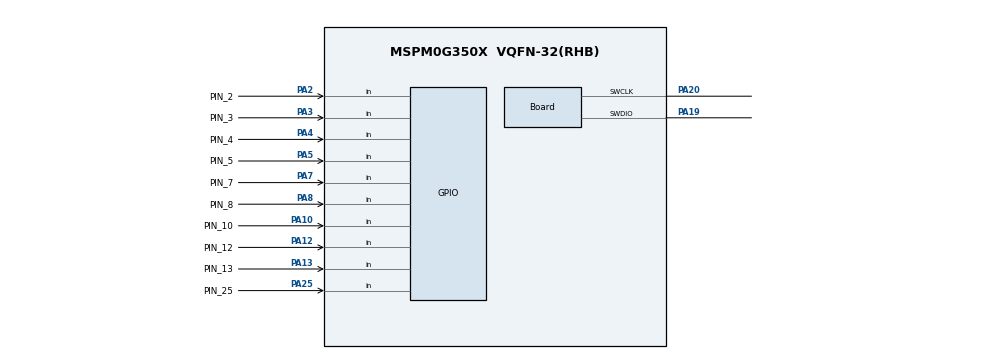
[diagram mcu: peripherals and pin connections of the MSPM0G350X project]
/**
 * @cliArgs --device "MSPM0G350X" --part "Default" --package "VQFN-32(RHB)" --product "mspm0_sdk@2.07.00.06"
 * @versions {"tool":"1.25.0+4268"}
 */

/**
 * Import the modules used in this configuration.
 */
const GPIO          = scripting.addModule("/ti/driverlib/GPIO", {}, false);
const GPIO1         = GPIO.addInstance();
const SYSCTL        = scripting.addModule("/ti/driverlib/SYSCTL");
const SYSTICK       = scripting.addModule("/ti/driverlib/SYSTICK");
const ProjectConfig = scripting.addModule("/ti/project_config/ProjectConfig");

/**
 * Write custom configuration values to the imported modules.
 */
const mux6       = system.clockTree["FCCSELCLKMUX"];
mux6.inputSelect = "FCCSELCLKMUX_SYSOSC";

const mux11       = system.clockTree["SYSCTLMUX"];
mux11.inputSelect = "SYSCTLMUX_LFCLK";

const oscillator2           = system.clockTree["SYSOSC"];
oscillator2.frequencySelect = 4;

GPIO1.$name                               = "GPIO_GRP_0";
GPIO1.port                                = "PORTA";
GPIO1.associatedPins.create(10);
GPIO1.associatedPins[0].assignedPin       = "4";
GPIO1.associatedPins[0].$name             = "PIN_4";
GPIO1.associatedPins[0].direction         = "INPUT";
GPIO1.associatedPins[0].pin.$assign       = "PA4";
GPIO1.associatedPins[1].$name             = "PIN_2";
GPIO1.associatedPins[1].assignedPin       = "2";
GPIO1.associatedPins[1].direction         = "INPUT";
GPIO1.associatedPins[1].interruptPriority = "0";
GPIO1.associatedPins[1].pin.$assign       = "PA2";
GPIO1.associatedPins[2].$name             = "PIN_5";
GPIO1.associatedPins[2].assignedPin       = "5";
GPIO1.associatedPins[2].direction         = "INPUT";
GPIO1.associatedPins[2].pin.$assign       = "PA5";
GPIO1.associatedPins[3].$name             = "PIN_8";
GPIO1.associatedPins[3].assignedPin       = "8";
GPIO1.associatedPins[3].direction         = "INPUT";
GPIO1.associatedPins[3].pin.$assign       = "PA8";
GPIO1.associatedPins[4].$name             = "PIN_10";
GPIO1.associatedPins[4].assignedPin       = "10";
GPIO1.associatedPins[4].direction         = "INPUT";
GPIO1.associatedPins[4].pin.$assign       = "PA10";
GPIO1.associatedPins[5].$name             = "PIN_25";
GPIO1.associatedPins[5].assignedPin       = "25";
GPIO1.associatedPins[5].direction         = "INPUT";
GPIO1.associatedPins[5].pin.$assign       = "PA25";
GPIO1.associatedPins[6].$name             = "PIN_13";
GPIO1.associatedPins[6].assignedPin       = "13";
GPIO1.associatedPins[6].direction         = "INPUT";
GPIO1.associatedPins[6].pin.$assign       = "PA13";
GPIO1.associatedPins[7].$name             = "PIN_12";
GPIO1.associatedPins[7].assignedPin       = "12";
GPIO1.associatedPins[7].direction         = "INPUT";
GPIO1.associatedPins[7].pin.$assign       = "PA12";
GPIO1.associatedPins[8].$name             = "PIN_7";
GPIO1.associatedPins[8].assignedPin       = "7";
GPIO1.associatedPins[8].direction         = "INPUT";
GPIO1.associatedPins[8].pin.$assign       = "PA7";
GPIO1.associatedPins[9].$name             = "PIN_3";
GPIO1.associatedPins[9].direction         = "INPUT";
GPIO1.associatedPins[9].assignedPin       = "3";
GPIO1.associatedPins[9].interruptPriority = "0";
GPIO1.associatedPins[9].polarity          = "RISE";
GPIO1.associatedPins[9].interruptEn       = true;
GPIO1.associatedPins[9].pin.$assign       = "PA3";

const Board                       = scripting.addModule("/ti/driverlib/Board", {}, false);
Board.peripheral.$assign          = "DEBUGSS";
Board.peripheral.swclkPin.$assign = "PA20";
Board.peripheral.swdioPin.$assign = "PA19";

SYSCTL.forceDefaultClkConfig = true;
SYSCTL.validateClkStatus     = true;
SYSCTL.SYSOSC_Freq           = 4000000;
SYSCTL.peripheral.$assign    = "SYSCTL";

ProjectConfig.migrationCondition = true;
